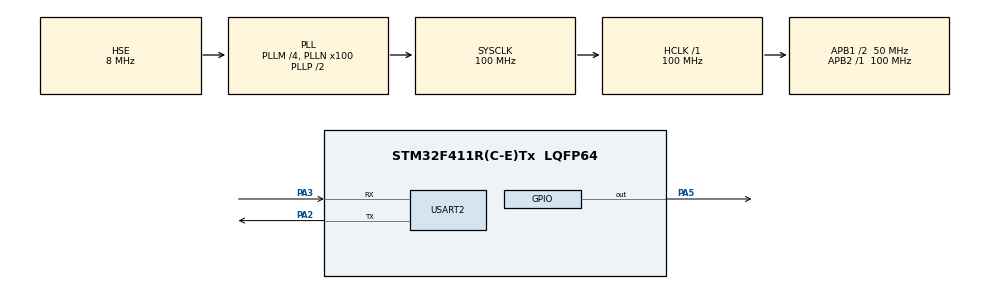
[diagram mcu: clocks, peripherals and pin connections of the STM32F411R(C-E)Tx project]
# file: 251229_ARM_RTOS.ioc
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FREERTOS.Tasks01=defaultTask,0,128,StartDefaultTask,Default,NULL,Dynamic,NULL,NULL;myTask02,0,128,StartTask02,Default,NULL,Dynamic,NULL,NULL;myTask03,0,128,StartTask03,Default,NULL,Dynamic,NULL,NULL;myTask04,0,128,StartTask04,Default,NULL,Dynamic,NULL,NULL
FREERTOS.configUSE_NEWLIB_REENTRANT=1
Mcu.Family=STM32F4
Mcu.Name=STM32F411R(C-E)Tx
Mcu.Package=LQFP64
NVIC.PriorityGroup=NVIC_PRIORITYGROUP_4
NVIC.TIM1_TRG_COM_TIM11_IRQn=true\:15\:0\:false\:false\:true\:false\:false\:true\:true
NVIC.TimeBase=TIM1_TRG_COM_TIM11_IRQn
NVIC.TimeBaseIP=TIM11
PA13.Mode=Serial_Wire
PA13.Signal=SYS_JTMS-SWDIO
PA14.Mode=Serial_Wire
PA14.Signal=SYS_JTCK-SWCLK
PA2.Mode=Asynchronous
PA2.Signal=USART2_TX
PA3.Mode=Asynchronous
PA3.Signal=USART2_RX
PA5.Signal=GPIO_Output
PH0\ -\ OSC_IN.Mode=HSE-External-Oscillator
PH0\ -\ OSC_IN.Signal=RCC_OSC_IN
PH1\ -\ OSC_OUT.Mode=HSE-External-Oscillator
PH1\ -\ OSC_OUT.Signal=RCC_OSC_OUT
ProjectManager.HeapSize=0x200
ProjectManager.StackSize=0x400
ProjectManager.TargetToolchain=STM32CubeIDE
RCC.48MHZClocksFreq_Value=50000000
RCC.AHBFreq_Value=100000000
RCC.APB1CLKDivider=RCC_HCLK_DIV2
RCC.APB1Freq_Value=50000000
RCC.APB1TimFreq_Value=100000000
RCC.APB2Freq_Value=100000000
RCC.APB2TimFreq_Value=100000000
RCC.CortexFreq_Value=100000000
RCC.HCLKFreq_Value=100000000
RCC.HSE_VALUE=8000000
RCC.HSI_VALUE=16000000
RCC.LSE_VALUE=32768
RCC.PLLM=4
RCC.PLLN=100
RCC.PLLSourceVirtual=RCC_PLLSOURCE_HSE
RCC.SYSCLKFreq_VALUE=100000000
RCC.SYSCLKSource=RCC_SYSCLKSOURCE_PLLCLK
RCC.VCOOutputFreq_Value=200000000
USART2.VirtualMode=VM_ASYNC
VP_FREERTOS_VS_CMSIS_V1.Mode=CMSIS_V1
VP_SYS_VS_tim11.Mode=TIM11
board=custom

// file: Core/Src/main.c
/* USER CODE BEGIN Header */
/**
  ******************************************************************************
  * @file           : main.c
  * @brief          : Main program body
  ******************************************************************************
  * @attention
  *
  * Copyright (c) 2025 STMicroelectronics.
  * All rights reserved.
  *
  * This software is licensed under terms that can be found in the LICENSE file
  * in the root directory of this software component.
  * If no LICENSE file comes with this software, it is provided AS-IS.
  *
  ******************************************************************************
  */
/* USER CODE END Header */
#include "main.h"
#include "cmsis_os.h"

/* USER CODE BEGIN Includes */
#include <stdio.h>
#include <string.h>
/* USER CODE END Includes */

UART_HandleTypeDef huart2;

osThreadId defaultTaskHandle;
osThreadId myTask02Handle;
osThreadId myTask03Handle;
osThreadId myTask04Handle;

void SystemClock_Config(void);
static void MX_GPIO_Init(void);
static void MX_USART2_UART_Init(void);
void StartDefaultTask(void const * argument);
void StartTask02(void const * argument);
void StartTask03(void const * argument);
void StartTask04(void const * argument);

int main(void)
{

  /* MCU Configuration--------------------------------------------------------*/

  /* Reset of all peripherals, Initializes the Flash interface and the Systick. */
  HAL_Init();

  /* Configure the system clock */
  SystemClock_Config();

  /* Initialize all configured peripherals */
  MX_GPIO_Init();
  MX_USART2_UART_Init();

  /* Create the thread(s) */
  /* definition and creation of defaultTask */
  osThreadDef(defaultTask, StartDefaultTask, osPriorityNormal, 0, 128);
  defaultTaskHandle = osThreadCreate(osThread(defaultTask), NULL);

  /* definition and creation of myTask02 */
  osThreadDef(myTask02, StartTask02, osPriorityNormal, 0, 128);
  myTask02Handle = osThreadCreate(osThread(myTask02), NULL);

  /* definition and creation of myTask03 */
  osThreadDef(myTask03, StartTask03, osPriorityNormal, 0, 128);
  myTask03Handle = osThreadCreate(osThread(myTask03), NULL);

  /* definition and creation of myTask04 */
  osThreadDef(myTask04, StartTask04, osPriorityNormal, 0, 128);
  myTask04Handle = osThreadCreate(osThread(myTask04), NULL);

  /* Start scheduler */
  osKernelStart();

  /* We should never get here as control is now taken by the scheduler */

  /* Infinite loop */
  while (1)
  {

  }
}

void SystemClock_Config(void)
{
  RCC_OscInitTypeDef RCC_OscInitStruct = {0};
  RCC_ClkInitTypeDef RCC_ClkInitStruct = {0};

  /** Configure the main internal regulator output voltage
  */
  __HAL_RCC_PWR_CLK_ENABLE();
  __HAL_PWR_VOLTAGESCALING_CONFIG(PWR_REGULATOR_VOLTAGE_SCALE1);

  /** Initializes the RCC Oscillators according to the specified parameters
  * in the RCC_OscInitTypeDef structure.
  */
  RCC_OscInitStruct.OscillatorType = RCC_OSCILLATORTYPE_HSE;
  RCC_OscInitStruct.HSEState = RCC_HSE_ON;
  RCC_OscInitStruct.PLL.PLLState = RCC_PLL_ON;
  RCC_OscInitStruct.PLL.PLLSource = RCC_PLLSOURCE_HSE;
  RCC_OscInitStruct.PLL.PLLM = 4;
  RCC_OscInitStruct.PLL.PLLN = 100;
  RCC_OscInitStruct.PLL.PLLP = RCC_PLLP_DIV2;
  RCC_OscInitStruct.PLL.PLLQ = 4;
  if (HAL_RCC_OscConfig(&RCC_OscInitStruct) != HAL_OK)
  {
    Error_Handler();
  }

  /** Initializes the CPU, AHB and APB buses clocks
  */
  RCC_ClkInitStruct.ClockType = RCC_CLOCKTYPE_HCLK|RCC_CLOCKTYPE_SYSCLK
                              |RCC_CLOCKTYPE_PCLK1|RCC_CLOCKTYPE_PCLK2;
  RCC_ClkInitStruct.SYSCLKSource = RCC_SYSCLKSOURCE_PLLCLK;
  RCC_ClkInitStruct.AHBCLKDivider = RCC_SYSCLK_DIV1;
  RCC_ClkInitStruct.APB1CLKDivider = RCC_HCLK_DIV2;
  RCC_ClkInitStruct.APB2CLKDivider = RCC_HCLK_DIV1;

  if (HAL_RCC_ClockConfig(&RCC_ClkInitStruct, FLASH_LATENCY_3) != HAL_OK)
  {
    Error_Handler();
  }
}

static void MX_USART2_UART_Init(void)
{

  huart2.Instance = USART2;
  huart2.Init.BaudRate = 115200;
  huart2.Init.WordLength = UART_WORDLENGTH_8B;
  huart2.Init.StopBits = UART_STOPBITS_1;
  huart2.Init.Parity = UART_PARITY_NONE;
  huart2.Init.Mode = UART_MODE_TX_RX;
  huart2.Init.HwFlowCtl = UART_HWCONTROL_NONE;
  huart2.Init.OverSampling = UART_OVERSAMPLING_16;
  if (HAL_UART_Init(&huart2) != HAL_OK)
  {
    Error_Handler();
  }

}

static void MX_GPIO_Init(void)
{
  GPIO_InitTypeDef GPIO_InitStruct = {0};

  /* GPIO Ports Clock Enable */
  __HAL_RCC_GPIOH_CLK_ENABLE();
  __HAL_RCC_GPIOA_CLK_ENABLE();

  /*Configure GPIO pin Output Level */
  HAL_GPIO_WritePin(GPIOA, GPIO_PIN_5, GPIO_PIN_RESET);

  /*Configure GPIO pin : PA5 */
  GPIO_InitStruct.Pin = GPIO_PIN_5;
  GPIO_InitStruct.Mode = GPIO_MODE_OUTPUT_PP;
  GPIO_InitStruct.Pull = GPIO_NOPULL;
  GPIO_InitStruct.Speed = GPIO_SPEED_FREQ_LOW;
  HAL_GPIO_Init(GPIOA, &GPIO_InitStruct);

}

void StartDefaultTask(void const * argument)
{
  /* USER CODE BEGIN 5 */
  /* Infinite loop */
  for(;;)
  {
	  for (uint32_t i = 0; i < 10000000; i++) {
		HAL_GPIO_TogglePin(GPIOA, GPIO_PIN_5);
	  }
    osDelay(500);
  }
  /* USER CODE END 5 */
}

void StartTask02(void const * argument)
{
  /* USER CODE BEGIN StartTask02 */
	char str[50];
	uint32_t task2Counter = 0;
  /* Infinite loop */
  for(;;)
  {
	  sprintf(str, "Task02 Counter : %d\n", task2Counter++);
	  HAL_UART_Transmit(&huart2, str, strlen(str), 1000);
    osDelay(1000);
  }
  /* USER CODE END StartTask02 */
}

void StartTask03(void const * argument)
{
  /* USER CODE BEGIN StartTask03 */
	char str[50];
	uint32_t task3Counter = 0;
  /* Infinite loop */
  for(;;)
  {
	  sprintf(str, "Task03 Counter : %d\n", task3Counter++);
	  HAL_UART_Transmit(&huart2, str, strlen(str), 1000);
    osDelay(5001);
  }
  /* USER CODE END StartTask03 */
}

void StartTask04(void const * argument)
{
  /* USER CODE BEGIN StartTask04 */
	char str[50];
	uint32_t task4Counter = 0;
  /* Infinite loop */
  for(;;)
  {
	  sprintf(str, "Task04 Counter : %d\n", task4Counter++);
	  HAL_UART_Transmit(&huart2, str, strlen(str), 1000);
    osDelay(2000);
  }
  /* USER CODE END StartTask04 */
}

void HAL_TIM_PeriodElapsedCallback(TIM_HandleTypeDef *htim)
{
  if (htim->Instance == TIM11)
  {
    HAL_IncTick();
  }
}

void Error_Handler(void)
{
  __disable_irq();
  while (1)
  {
  }
}
